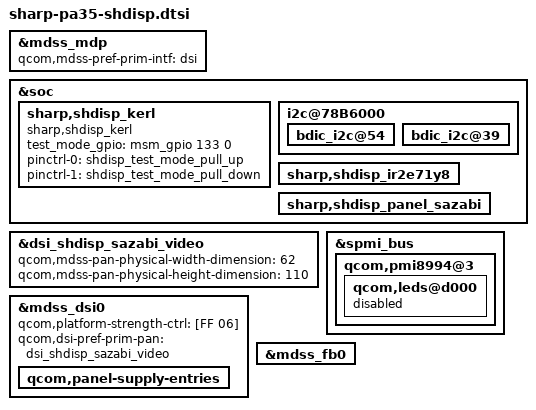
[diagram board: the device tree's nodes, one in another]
/* Copyright (c) 2014, The Linux Foundation. All rights reserved.
 *
 * This program is free software; you can redistribute it and/or modify
 * it under the terms of the GNU General Public License version 2 and
 * only version 2 as published by the Free Software Foundation.
 *
 * This program is distributed in the hope that it will be useful,
 * but WITHOUT ANY WARRANTY; without even the implied warranty of
 * MERCHANTABILITY or FITNESS FOR A PARTICULAR PURPOSE.  See the
 * GNU General Public License for more details.
 */

#include "sharp-shdisp-ir2e71y8.dtsi"
#include "sharp-shdisp-dsi-panel-sazabi-pa-720p-video.dtsi"
#include "sharp-shdisp-sazabi.dtsi"

&mdss_mdp {
		/delete-node/ qcom,mdss_dsi_truly_1080p_video;
		/delete-node/ qcom,mdss_dsi_truly_1080p_cmd;
		/delete-node/ qcom,mdss_dsi_otm1906c_1080p_cmd;
		/delete-node/ qcom,mdss_dsi_hx8399a_1080p_video;
		/delete-node/ qcom,mdss_dsi_sim_video;
		/delete-node/ qcom,mdss_dsi_sim_cmd;
		/delete-node/ qcom,mdss_dsi_sharp_1080p_cmd;
};

&soc {
	sharp,shdisp_kerl {
		status = "disable";
		compatible = "sharp,shdisp_kerl";
		test_mode_gpio = <&msm_gpio 133 0>;

		pinctrl-names = "test_mode_pull_up", "test_mode_pull_down";
		pinctrl-0 = <&shdisp_test_mode_pull_up>;
		pinctrl-1 = <&shdisp_test_mode_pull_down>;
	};
};

&soc {
	i2c@78B6000 {
		bdic_i2c@54 {
			status = "ok";
		};

		bdic_i2c@39 {
			status = "ok";
		};
	};
};

&soc {

	sharp,shdisp_kerl {
		status = "ok";
	};
	sharp,shdisp_ir2e71y8 {
		status = "ok";
	};
	sharp,shdisp_panel_sazabi {
		status = "ok";
	};
};

&dsi_shdisp_sazabi_video {
	status = "ok";

	qcom,mdss-pan-physical-width-dimension = <62>;
	qcom,mdss-pan-physical-height-dimension = <110>;
};


&mdss_mdp {
	qcom,mdss-pref-prim-intf = "dsi";
};

&mdss_dsi0 {
	qcom,platform-strength-ctrl = [FF 06];
	qcom,dsi-pref-prim-pan=<&dsi_shdisp_sazabi_video>;

	/delete-property/ pinctrl-names;
	/delete-property/ pinctrl-0;
	/delete-property/ pinctrl-1;

	/delete-property/ vdd-supply;
	/delete-property/ lab-supply;
	/delete-property/ ibb-supply;

	/delete-property/ qcom,dsi-panel-bias-vreg;
	/delete-property/ qcom,platform-reset-gpio;
	/delete-property/ qcom,platform-bklight-en-gpio;
	/delete-property/ qcom,platform-enable-gpio;

	qcom,panel-supply-entries {
		/delete-node/ qcom,panel-supply-entry@0;
		/delete-node/ qcom,panel-supply-entry@2;
		/delete-node/ qcom,panel-supply-entry@3;
	};
};

&spmi_bus{
    qcom,pmi8994@3{
		qcom,leds@d000 {
            status = "disabled";
        };
    };
};

&mdss_fb0 {
	/delete-property/ qcom,mdss-fb-splash-logo-enabled;
};
